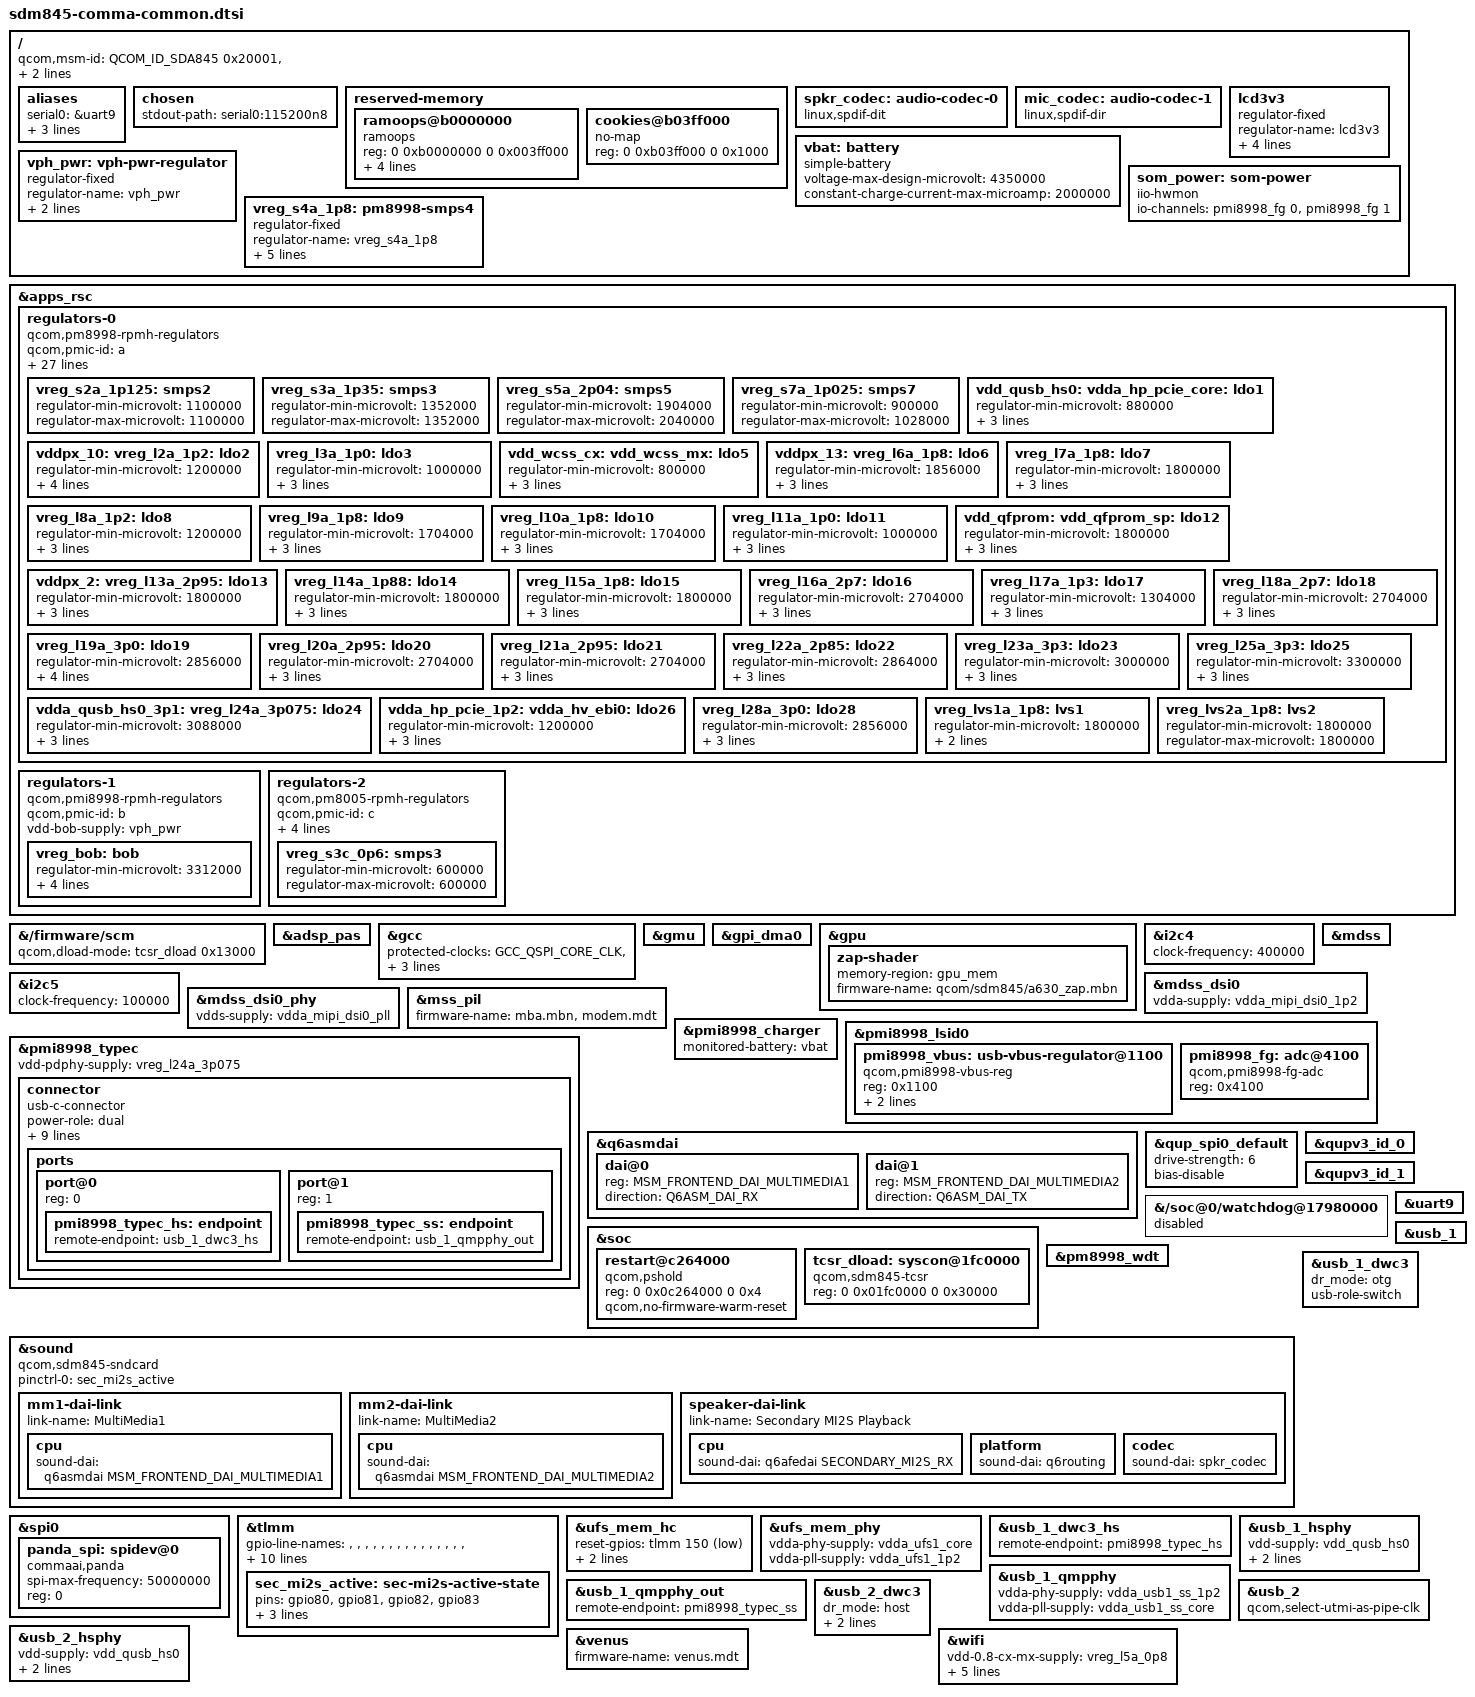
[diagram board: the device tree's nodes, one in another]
/dts-v1/;

#include <dt-bindings/arm/qcom,ids.h>
#include <dt-bindings/regulator/qcom,rpmh-regulator.h>
#include <dt-bindings/sound/qcom,q6afe.h>
#include <dt-bindings/sound/qcom,q6asm.h>
#include <dt-bindings/usb/pd.h>
#include "sdm845.dtsi"
#include "pm8998.dtsi"
#include "pmi8998.dtsi"

/ {
	qcom,msm-id = <QCOM_ID_SDA845 0x20001>, <QCOM_ID_SDM845 0x20001>,
		      <QCOM_ID_SDM845 0x20000>, <348 0x20001>;

	aliases {
		serial0 = &uart9;
		i2c0 = &i2c10;
		i2c1 = &i2c4;
		i2c2 = &i2c5;
	};

	chosen {
		stdout-path = "serial0:115200n8";
	};

	reserved-memory {
		ramoops@b0000000 {
			compatible = "ramoops";
			reg = <0 0xb0000000 0 0x003ff000>;
			record-size = <0x40000>;
			console-size = <0x40000>;
			ftrace-size = <0x40000>;
			pmsg-size = <0x200000>;
		};

		/* ABL's power-drop cookie is at the end of this page. */
		cookies@b03ff000 {
			no-map;
			reg = <0 0xb03ff000 0 0x1000>;
		};
	};

	spkr_codec: audio-codec-0 {
		compatible = "linux,spdif-dit";
		#sound-dai-cells = <0>;
	};

	mic_codec: audio-codec-1 {
		compatible = "linux,spdif-dir";
		#sound-dai-cells = <0>;
	};

	/*
	 * There is no battery: VBAT is a rail on the SoM regulated from the
	 * main supply. When the charger takes power from USB, it runs with the
	 * float voltage and fast charge current stock uses.
	 */
	vbat: battery {
		compatible = "simple-battery";
		voltage-max-design-microvolt = <4350000>;
		constant-charge-current-max-microamp = <2000000>;
	};

	lcd3v3: lcd3v3 {
		compatible = "regulator-fixed";
		regulator-name = "lcd3v3";
		regulator-min-microvolt = <3300000>;
		regulator-max-microvolt = <3300000>;
		gpio = <&pm8998_gpios 13 GPIO_ACTIVE_HIGH>;
		regulator-boot-on;
	};

	vph_pwr: vph-pwr-regulator {
		compatible = "regulator-fixed";
		regulator-name = "vph_pwr";
		regulator-min-microvolt = <3700000>;
		regulator-max-microvolt = <3700000>;
	};

	/* SoM power draw, read by openpilot on every device */
	som_power: som-power {
		compatible = "iio-hwmon";
		io-channels = <&pmi8998_fg 0>, <&pmi8998_fg 1>;
	};

	/*
	 * Apparently RPMh does not provide support for PM8998 S4 because it
	 * is always-on; model it as a fixed regulator.
	 */
	vreg_s4a_1p8: pm8998-smps4 {
		compatible = "regulator-fixed";
		regulator-name = "vreg_s4a_1p8";

		regulator-min-microvolt = <1800000>;
		regulator-max-microvolt = <1800000>;

		regulator-always-on;
		regulator-boot-on;

		vin-supply = <&vph_pwr>;
	};
};

&apps_rsc {
	regulators-0 {
		compatible = "qcom,pm8998-rpmh-regulators";
		qcom,pmic-id = "a";

		vdd-s1-supply = <&vph_pwr>;
		vdd-s2-supply = <&vph_pwr>;
		vdd-s3-supply = <&vph_pwr>;
		vdd-s4-supply = <&vph_pwr>;
		vdd-s5-supply = <&vph_pwr>;
		vdd-s6-supply = <&vph_pwr>;
		vdd-s7-supply = <&vph_pwr>;
		vdd-s8-supply = <&vph_pwr>;
		vdd-s9-supply = <&vph_pwr>;
		vdd-s10-supply = <&vph_pwr>;
		vdd-s11-supply = <&vph_pwr>;
		vdd-s12-supply = <&vph_pwr>;
		vdd-s13-supply = <&vph_pwr>;
		vdd-l1-l27-supply = <&vreg_s7a_1p025>;
		vdd-l2-l8-l17-supply = <&vreg_s3a_1p35>;
		vdd-l3-l11-supply = <&vreg_s7a_1p025>;
		vdd-l4-l5-supply = <&vreg_s7a_1p025>;
		vdd-l6-supply = <&vph_pwr>;
		vdd-l7-l12-l14-l15-supply = <&vreg_s5a_2p04>;
		vdd-l9-supply = <&vreg_bob>;
		vdd-l10-l23-l25-supply = <&vreg_bob>;
		vdd-l13-l19-l21-supply = <&vreg_bob>;
		vdd-l16-l28-supply = <&vreg_bob>;
		vdd-l18-l22-supply = <&vreg_bob>;
		vdd-l20-l24-supply = <&vreg_bob>;
		vdd-l26-supply = <&vreg_s3a_1p35>;
		vin-lvs-1-2-supply = <&vreg_s4a_1p8>;

		vreg_s2a_1p125: smps2 {
			regulator-min-microvolt = <1100000>;
			regulator-max-microvolt = <1100000>;
		};

		vreg_s3a_1p35: smps3 {
			regulator-min-microvolt = <1352000>;
			regulator-max-microvolt = <1352000>;
		};

		vreg_s5a_2p04: smps5 {
			regulator-min-microvolt = <1904000>;
			regulator-max-microvolt = <2040000>;
		};

		vreg_s7a_1p025: smps7 {
			regulator-min-microvolt = <900000>;
			regulator-max-microvolt = <1028000>;
		};

		vdd_qusb_hs0:
		vdda_hp_pcie_core:
		vdda_mipi_csi0_0p9:
		vdda_mipi_csi1_0p9:
		vdda_mipi_csi2_0p9:
		vdda_mipi_dsi0_pll:
		vdda_mipi_dsi1_pll:
		vdda_qlink_lv:
		vdda_qlink_lv_ck:
		vdda_qrefs_0p875:
		vdda_pcie_core:
		vdda_pll_cc_ebi01:
		vdda_pll_cc_ebi23:
		vdda_sp_sensor:
		vdda_ufs1_core:
		vdda_ufs2_core:
		vdda_usb1_ss_core:
		vdda_usb2_ss_core:
		vreg_l1a_0p875: ldo1 {
			regulator-min-microvolt = <880000>;
			regulator-max-microvolt = <880000>;
			regulator-initial-mode = <RPMH_REGULATOR_MODE_HPM>;
		};

		vddpx_10:
		vreg_l2a_1p2: ldo2 {
			regulator-min-microvolt = <1200000>;
			regulator-max-microvolt = <1200000>;
			regulator-initial-mode = <RPMH_REGULATOR_MODE_HPM>;
			regulator-always-on;
		};

		vreg_l3a_1p0: ldo3 {
			regulator-min-microvolt = <1000000>;
			regulator-max-microvolt = <1000000>;
			regulator-initial-mode = <RPMH_REGULATOR_MODE_HPM>;
		};

		vdd_wcss_cx:
		vdd_wcss_mx:
		vdda_wcss_pll:
		vreg_l5a_0p8: ldo5 {
			regulator-min-microvolt = <800000>;
			regulator-max-microvolt = <800000>;
			regulator-initial-mode = <RPMH_REGULATOR_MODE_HPM>;
		};

		vddpx_13:
		vreg_l6a_1p8: ldo6 {
			regulator-min-microvolt = <1856000>;
			regulator-max-microvolt = <1856000>;
			regulator-initial-mode = <RPMH_REGULATOR_MODE_HPM>;
		};

		vreg_l7a_1p8: ldo7 {
			regulator-min-microvolt = <1800000>;
			regulator-max-microvolt = <1800000>;
			regulator-initial-mode = <RPMH_REGULATOR_MODE_HPM>;
		};

		vreg_l8a_1p2: ldo8 {
			regulator-min-microvolt = <1200000>;
			regulator-max-microvolt = <1248000>;
			regulator-initial-mode = <RPMH_REGULATOR_MODE_HPM>;
		};

		vreg_l9a_1p8: ldo9 {
			regulator-min-microvolt = <1704000>;
			regulator-max-microvolt = <2928000>;
			regulator-initial-mode = <RPMH_REGULATOR_MODE_HPM>;
		};

		vreg_l10a_1p8: ldo10 {
			regulator-min-microvolt = <1704000>;
			regulator-max-microvolt = <2928000>;
			regulator-initial-mode = <RPMH_REGULATOR_MODE_HPM>;
		};

		vreg_l11a_1p0: ldo11 {
			regulator-min-microvolt = <1000000>;
			regulator-max-microvolt = <1048000>;
			regulator-initial-mode = <RPMH_REGULATOR_MODE_HPM>;
		};

		vdd_qfprom:
		vdd_qfprom_sp:
		vdda_apc1_cs_1p8:
		vdda_gfx_cs_1p8:
		vdda_qrefs_1p8:
		vdda_qusb_hs0_1p8:
		vddpx_11:
		vreg_l12a_1p8: ldo12 {
			regulator-min-microvolt = <1800000>;
			regulator-max-microvolt = <1800000>;
			regulator-initial-mode = <RPMH_REGULATOR_MODE_HPM>;
		};

		vddpx_2:
		vreg_l13a_2p95: ldo13 {
			regulator-min-microvolt = <1800000>;
			regulator-max-microvolt = <2960000>;
			regulator-initial-mode = <RPMH_REGULATOR_MODE_HPM>;
		};

		vreg_l14a_1p88: ldo14 {
			regulator-min-microvolt = <1800000>;
			regulator-max-microvolt = <1800000>;
			regulator-initial-mode = <RPMH_REGULATOR_MODE_HPM>;
		};

		vreg_l15a_1p8: ldo15 {
			regulator-min-microvolt = <1800000>;
			regulator-max-microvolt = <1800000>;
			regulator-initial-mode = <RPMH_REGULATOR_MODE_HPM>;
		};

		vreg_l16a_2p7: ldo16 {
			regulator-min-microvolt = <2704000>;
			regulator-max-microvolt = <2704000>;
			regulator-initial-mode = <RPMH_REGULATOR_MODE_HPM>;
		};

		vreg_l17a_1p3: ldo17 {
			regulator-min-microvolt = <1304000>;
			regulator-max-microvolt = <1304000>;
			regulator-initial-mode = <RPMH_REGULATOR_MODE_HPM>;
		};

		vreg_l18a_2p7: ldo18 {
			regulator-min-microvolt = <2704000>;
			regulator-max-microvolt = <2960000>;
			regulator-initial-mode = <RPMH_REGULATOR_MODE_HPM>;
		};

		vreg_l19a_3p0: ldo19 {
			regulator-min-microvolt = <2856000>;
			regulator-max-microvolt = <3104000>;
			regulator-initial-mode = <RPMH_REGULATOR_MODE_HPM>;
		};

		vreg_l20a_2p95: ldo20 {
			regulator-min-microvolt = <2704000>;
			regulator-max-microvolt = <2960000>;
			regulator-initial-mode = <RPMH_REGULATOR_MODE_HPM>;
		};

		vreg_l21a_2p95: ldo21 {
			regulator-min-microvolt = <2704000>;
			regulator-max-microvolt = <2960000>;
			regulator-initial-mode = <RPMH_REGULATOR_MODE_HPM>;
		};

		vreg_l22a_2p85: ldo22 {
			regulator-min-microvolt = <2864000>;
			regulator-max-microvolt = <3312000>;
			regulator-initial-mode = <RPMH_REGULATOR_MODE_HPM>;
		};

		vreg_l23a_3p3: ldo23 {
			regulator-min-microvolt = <3000000>;
			regulator-max-microvolt = <3312000>;
			regulator-initial-mode = <RPMH_REGULATOR_MODE_HPM>;
		};

		vdda_qusb_hs0_3p1:
		vreg_l24a_3p075: ldo24 {
			regulator-min-microvolt = <3088000>;
			regulator-max-microvolt = <3088000>;
			regulator-initial-mode = <RPMH_REGULATOR_MODE_HPM>;
		};

		vreg_l25a_3p3: ldo25 {
			regulator-min-microvolt = <3300000>;
			regulator-max-microvolt = <3312000>;
			regulator-initial-mode = <RPMH_REGULATOR_MODE_HPM>;
		};

		vdda_hp_pcie_1p2:
		vdda_hv_ebi0:
		vdda_hv_ebi1:
		vdda_hv_ebi2:
		vdda_hv_ebi3:
		vdda_mipi_csi_1p25:
		vdda_mipi_dsi0_1p2:
		vdda_mipi_dsi1_1p2:
		vdda_pcie_1p2:
		vdda_ufs1_1p2:
		vdda_ufs2_1p2:
		vdda_usb1_ss_1p2:
		vdda_usb2_ss_1p2:
		vreg_l26a_1p2: ldo26 {
			regulator-min-microvolt = <1200000>;
			regulator-max-microvolt = <1200000>;
			regulator-initial-mode = <RPMH_REGULATOR_MODE_HPM>;
		};

		vreg_l28a_3p0: ldo28 {
			regulator-min-microvolt = <2856000>;
			regulator-max-microvolt = <3008000>;
			regulator-initial-mode = <RPMH_REGULATOR_MODE_HPM>;
		};

		vreg_lvs1a_1p8: lvs1 {
			regulator-min-microvolt = <1800000>;
			regulator-max-microvolt = <1800000>;
		};

		vreg_lvs2a_1p8: lvs2 {
			regulator-min-microvolt = <1800000>;
			regulator-max-microvolt = <1800000>;
		};
	};

	regulators-1 {
		compatible = "qcom,pmi8998-rpmh-regulators";
		qcom,pmic-id = "b";

		vdd-bob-supply = <&vph_pwr>;

		vreg_bob: bob {
			regulator-min-microvolt = <3312000>;
			regulator-max-microvolt = <3600000>;
			regulator-initial-mode = <RPMH_REGULATOR_MODE_AUTO>;
			regulator-allow-bypass;
		};
	};

	regulators-2 {
		compatible = "qcom,pm8005-rpmh-regulators";
		qcom,pmic-id = "c";

		vdd-s1-supply = <&vph_pwr>;
		vdd-s2-supply = <&vph_pwr>;
		vdd-s3-supply = <&vph_pwr>;
		vdd-s4-supply = <&vph_pwr>;

		vreg_s3c_0p6: smps3 {
			regulator-min-microvolt = <600000>;
			regulator-max-microvolt = <600000>;
		};
	};
};

&{/firmware/scm} {
	qcom,dload-mode = <&tcsr_dload 0x13000>;
};

&adsp_pas {
	status = "okay";
};

&gcc {
	protected-clocks = <GCC_QSPI_CORE_CLK>,
			   <GCC_QSPI_CORE_CLK_SRC>,
			   <GCC_QSPI_CNOC_PERIPH_AHB_CLK>,
			   <GCC_LPASS_Q6_AXI_CLK>,
			   <GCC_LPASS_SWAY_CLK>;
};

&gmu {
	status = "okay";
};

&gpi_dma0 {
	status = "okay";
};

&gpu {
	status = "okay";

	zap-shader {
		memory-region = <&gpu_mem>;
		firmware-name = "qcom/sdm845/a630_zap.mbn";
	};
};

&i2c4 {
	clock-frequency = <400000>;

	status = "okay";
};

&i2c5 {
	clock-frequency = <100000>;

	status = "okay";
};

&mdss {
	status = "okay";
};

&mdss_dsi0 {
	vdda-supply = <&vdda_mipi_dsi0_1p2>;

	status = "okay";
};

&mdss_dsi0_phy {
	vdds-supply = <&vdda_mipi_dsi0_pll>;

	status = "okay";
};

&mss_pil {
	firmware-name = "mba.mbn", "modem.mdt";

	status = "okay";
};

/*
 * The PMI8998 charger is the only writer of the input suspend bits. It also
 * suspends USBIN while the Type-C port below sources VBUS, so the charger
 * doesn't draw from its own boost.
 */
&pmi8998_charger {
	monitored-battery = <&vbat>;

	status = "okay";
};

&pmi8998_lsid0 {
	pmi8998_vbus: usb-vbus-regulator@1100 {
		compatible = "qcom,pmi8998-vbus-reg";
		reg = <0x1100>;
		regulator-min-microamp = <1500000>;
		regulator-max-microamp = <1500000>;
	};

	/* No battery: the fuel gauge measures the SoM's VBAT rail. */
	pmi8998_fg: adc@4100 {
		compatible = "qcom,pmi8998-fg-adc";
		reg = <0x4100>;
		#io-channel-cells = <1>;
	};
};

/*
 * The external USB-C port is a device to a PC, and a host plus 5 V source
 * to peripherals such as the comma eGPU dock.
 */
&pmi8998_typec {
	vdd-pdphy-supply = <&vreg_l24a_3p075>;

	status = "okay";

	connector {
		compatible = "usb-c-connector";
		power-role = "dual";
		data-role = "dual";
		try-power-role = "sink";
		self-powered;
		vbus-supply = <&pmi8998_vbus>;
		source-pdos = <PDO_FIXED(5000, 1500, PDO_FIXED_DUAL_ROLE |
					 PDO_FIXED_USB_COMM | PDO_FIXED_DATA_SWAP)>;
		sink-pdos = <PDO_FIXED(5000, 3000, PDO_FIXED_DUAL_ROLE |
				       PDO_FIXED_USB_COMM | PDO_FIXED_DATA_SWAP)>;
		op-sink-microwatt = <7500000>;

		ports {
			#address-cells = <1>;
			#size-cells = <0>;

			port@0 {
				reg = <0>;

				pmi8998_typec_hs: endpoint {
					remote-endpoint = <&usb_1_dwc3_hs>;
				};
			};

			port@1 {
				reg = <1>;

				pmi8998_typec_ss: endpoint {
					remote-endpoint = <&usb_1_qmpphy_out>;
				};
			};
		};
	};
};

&q6asmdai {
	dai@0 {
		reg = <MSM_FRONTEND_DAI_MULTIMEDIA1>;
		direction = <Q6ASM_DAI_RX>;
	};

	dai@1 {
		reg = <MSM_FRONTEND_DAI_MULTIMEDIA2>;
		direction = <Q6ASM_DAI_TX>;
	};
};

/* panda SPI, as configured by the downstream kernel */
&qup_spi0_default {
	drive-strength = <6>;
	bias-disable;
};

&qupv3_id_0 {
	status = "okay";
};

&qupv3_id_1 {
	status = "okay";
};

&soc {
	restart@c264000 {
		compatible = "qcom,pshold";
		reg = <0 0x0c264000 0 0x4>;
		qcom,no-firmware-warm-reset;
	};

	tcsr_dload: syscon@1fc0000 {
		compatible = "qcom,sdm845-tcsr", "syscon";
		reg = <0 0x01fc0000 0 0x30000>;
	};
};

/*
 * TZ on these devices does not reset on an APSS watchdog bite: with SDI
 * disabled it parks the CPU that takes the bite, otherwise it goes to
 * ramdump. Use the PMIC watchdog, whose bite resets the PMIC directly.
 */
&{/soc@0/watchdog@17980000} {
	status = "disabled";
};

&pm8998_wdt {
	status = "okay";
};

&sound {
	compatible = "qcom,sdm845-sndcard";
	pinctrl-names = "default";
	pinctrl-0 = <&sec_mi2s_active>;

	mm1-dai-link {
		link-name = "MultiMedia1";
		cpu {
			sound-dai = <&q6asmdai MSM_FRONTEND_DAI_MULTIMEDIA1>;
		};
	};

	mm2-dai-link {
		link-name = "MultiMedia2";
		cpu {
			sound-dai = <&q6asmdai MSM_FRONTEND_DAI_MULTIMEDIA2>;
		};
	};

	speaker-dai-link {
		link-name = "Secondary MI2S Playback";
		cpu {
			sound-dai = <&q6afedai SECONDARY_MI2S_RX>;
		};
		platform {
			sound-dai = <&q6routing>;
		};
		codec {
			sound-dai = <&spkr_codec>;
		};
	};
};

&spi0 {
	status = "okay";

	panda_spi: spidev@0 {
		compatible = "commaai,panda";
		spi-max-frequency = <50000000>;
		reg = <0>;
	};
};

&tlmm {
	/*
	 * The lines userspace drives, named as in openpilot's GPIO class
	 * (common/hardware/comma/pins.py). Look them up by name (libgpiod)
	 * instead of by number: sysfs numbers depend on probe order.
	 */
	gpio-line-names =
		/*   0 */ "", "", "", "", "", "", "", "",
		/*   8 */ "", "", "", "", "", "", "", "",
		/*  16 */ "", "", "", "", "", "", "", "",
		/*  24 */ "", "", "", "", "", "", "HUB_RST_N", "",
		/*  32 */ "UBLOX_RST_N", "UBLOX_SAFEBOOT_N", "GNSS_PWR_EN", "", "", "", "", "",
		/*  40 */ "", "STM_PWR_EN_N", "", "", "", "", "", "",
		/*  48 */ "", "SOM_ST_IO", "LTE_RST_N", "", "LTE_BOOT", "", "", "",
		/*  56 */ "", "", "", "", "", "", "", "",
		/*  64 */ "", "", "", "", "", "", "", "",
		/*  72 */ "", "", "", "", "", "", "", "",
		/*  80 */ "", "", "", "", "LSM_INT", "", "", "",
		/*  88 */ "", "", "", "", "", "", "", "",
		/*  96 */ "", "", "", "", "", "", "", "",
		/* 104 */ "", "", "", "", "", "", "", "",
		/* 112 */ "", "", "", "", "LTE_PWRKEY", "", "", "",
		/* 120 */ "", "", "", "", "STM_RST_N", "", "", "",
		/* 128 */ "", "", "", "", "", "", "STM_BOOT0", "",
		/* 136 */ "", "", "", "", "", "", "", "",
		/* 144 */ "", "", "", "", "", "";

	sec_mi2s_active: sec-mi2s-active-state {
		pins = "gpio80", "gpio81", "gpio82", "gpio83";
		function = "sec_mi2s";
		drive-strength = <8>;
		bias-disable;
	};
};

&uart9 {
	status = "okay";
};

&ufs_mem_hc {
	reset-gpios = <&tlmm 150 GPIO_ACTIVE_LOW>;

	vcc-supply = <&vreg_l20a_2p95>;
	vcc-max-microamp = <600000>;

	status = "okay";
};

&ufs_mem_phy {
	vdda-phy-supply = <&vdda_ufs1_core>;
	vdda-pll-supply = <&vdda_ufs1_1p2>;

	status = "okay";
};

&usb_1 {
	status = "okay";
};

&usb_1_dwc3 {
	dr_mode = "otg";
	usb-role-switch;
};

&usb_1_dwc3_hs {
	remote-endpoint = <&pmi8998_typec_hs>;
};

&usb_1_hsphy {
	vdd-supply = <&vdd_qusb_hs0>;
	vdda-phy-dpdm-supply = <&vdda_qusb_hs0_3p1>;
	vdda-pll-supply = <&vdda_qusb_hs0_1p8>;

	status = "okay";
};

&usb_1_qmpphy {
	vdda-phy-supply = <&vdda_usb1_ss_1p2>;
	vdda-pll-supply = <&vdda_usb1_ss_core>;

	status = "okay";
};

&usb_1_qmpphy_out {
	remote-endpoint = <&pmi8998_typec_ss>;
};

/* The secondary USB host has only the internal LTE modem on it, a USB 2.0 device */
&usb_2 {
	/* No USB 3 PHY: clock the PIPE interface from UTMI */
	qcom,select-utmi-as-pipe-clk;

	status = "okay";
};

&usb_2_dwc3 {
	dr_mode = "host";
	maximum-speed = "high-speed";

	/* Drop the unused USB 3 PHY */
	phys = <&usb_2_hsphy>;
	phy-names = "usb2-phy";
};

&usb_2_hsphy {
	vdd-supply = <&vdd_qusb_hs0>;
	vdda-pll-supply = <&vdda_qusb_hs0_1p8>;
	vdda-phy-dpdm-supply = <&vdda_qusb_hs0_3p1>;

	status = "okay";
};

&venus {
	firmware-name = "venus.mdt";

	status = "okay";
};

/* IMU supplies */
&vreg_l19a_3p0 {
	regulator-always-on;
};

&vreg_lvs1a_1p8 {
	regulator-always-on;
};

&wifi {
	vdd-0.8-cx-mx-supply = <&vreg_l5a_0p8>;
	vdd-1.3-rfa-supply = <&vreg_l17a_1p3>;
	vdd-1.8-xo-supply = <&vreg_l7a_1p8>;
	vdd-3.3-ch0-supply = <&vreg_l25a_3p3>;
	vdd-3.3-ch1-supply = <&vreg_l23a_3p3>;

	qcom,snoc-host-cap-skip-quirk;

	status = "okay";
};

#include "sdm845-comma-spectra.dtsi"
